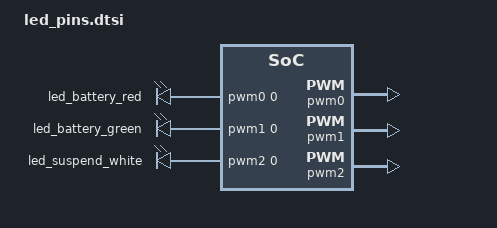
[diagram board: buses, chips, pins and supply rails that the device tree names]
/* Copyright 2025 The ChromiumOS Authors
 * Use of this source code is governed by a BSD-style license that can be
 * found in the LICENSE file.
 */

/ {
	pwmleds {
		compatible = "pwm-leds";
		led_battery_red: ec_led2_l {
			pwms = <&pwm0 0 PWM_HZ(100) PWM_POLARITY_INVERTED>;
		};
		led_battery_green: ec_led3_l {
			pwms = <&pwm1 0 PWM_HZ(100) PWM_POLARITY_INVERTED>;
		};
		led_suspend_white: ec_led1_l {
			pwms = <&pwm2 0 PWM_HZ(100) PWM_POLARITY_INVERTED>;
		};
	};

	pwm-led-pins {
		compatible = "cros-ec,pwm-led-pins";

		battery_led: battery-led {
			led-id = "EC_LED_ID_BATTERY_LED";
			led-pwms = <&led_battery_red &led_battery_green >;

			color-battery-off {
				led-color = "LED_OFF";
				led-values = <0 0>;
			};

			color-battery-red {
				led-color = "LED_RED";
				led-values = <100 0>;
			};

			color-battery-green {
				led-color = "LED_GREEN";
				led-values = <0 100>;
			};

			color-battery-amber {
				led-color = "LED_AMBER";
				led-values = <70 50>;
			};
		};

		power_led: power-led {
			led-id = "EC_LED_ID_POWER_LED";
			led-pwms = <&led_suspend_white>;

			color-power-off {
				led-color = "LED_OFF";
				led-values = <0>;
			};

			color-power-white {
				led-color = "LED_WHITE";
				led-values = <100>;
			};
		};
	};
};

/* Red LED */
&pwm0 {
	status = "okay";
	clock-bus = "NPCX_CLOCK_BUS_LFCLK";
	pinctrl-0 = <&pwm0_gpc3>;
	pinctrl-names = "default";
};

/* green LED */
&pwm1 {
	status = "okay";
	clock-bus = "NPCX_CLOCK_BUS_LFCLK";
	pinctrl-0 = <&pwm1_gpc2>;
	pinctrl-names = "default";
};

/* white LED */
&pwm2 {
	status = "okay";
	clock-bus = "NPCX_CLOCK_BUS_LFCLK";
	pinctrl-0 = <&pwm2_gpc4>;
	pinctrl-names = "default";
};
